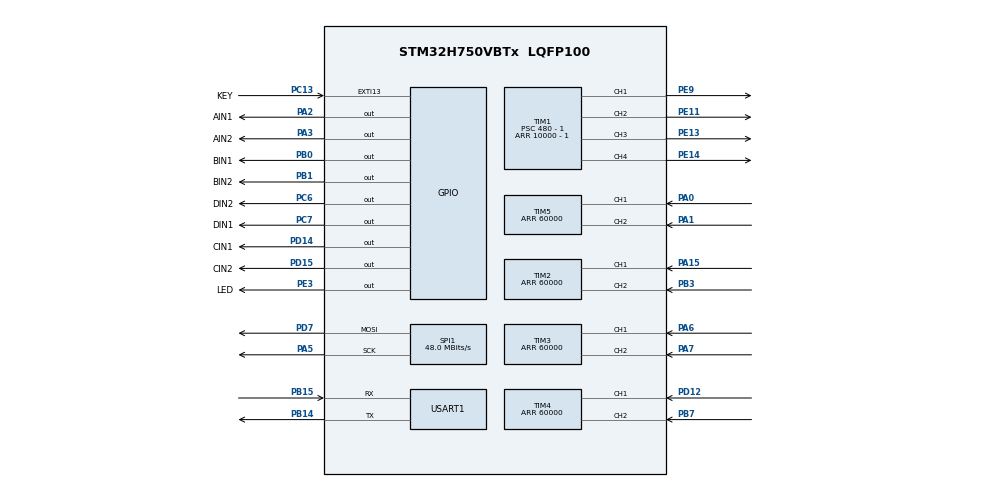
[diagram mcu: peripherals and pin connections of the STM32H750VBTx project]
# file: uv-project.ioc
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Dma.Request0=TIM2_UP
Dma.TIM2_UP.0.Direction=DMA_PERIPH_TO_MEMORY
Dma.TIM2_UP.0.EventEnable=DISABLE
Dma.TIM2_UP.0.FIFOMode=DMA_FIFOMODE_DISABLE
Dma.TIM2_UP.0.Instance=DMA1_Stream2
Dma.TIM2_UP.0.MemDataAlignment=DMA_MDATAALIGN_WORD
Dma.TIM2_UP.0.MemInc=DMA_MINC_ENABLE
Dma.TIM2_UP.0.Mode=DMA_NORMAL
Dma.TIM2_UP.0.PeriphDataAlignment=DMA_PDATAALIGN_WORD
Dma.TIM2_UP.0.PeriphInc=DMA_PINC_DISABLE
Dma.TIM2_UP.0.Polarity=HAL_DMAMUX_REQ_GEN_RISING
Dma.TIM2_UP.0.Priority=DMA_PRIORITY_LOW
Dma.TIM2_UP.0.RequestNumber=1
Dma.TIM2_UP.0.SignalID=NONE
Dma.TIM2_UP.0.SyncEnable=DISABLE
Dma.TIM2_UP.0.SyncPolarity=HAL_DMAMUX_SYNC_NO_EVENT
Dma.TIM2_UP.0.SyncRequestNumber=1
Dma.TIM2_UP.0.SyncSignalID=NONE
Mcu.Family=STM32H7
Mcu.Name=STM32H750VBTx
Mcu.Package=LQFP100
NVIC.DMA1_Stream2_IRQn=true\:0\:0\:false\:false\:true\:false\:true\:true
NVIC.EXTI15_10_IRQn=true\:0\:0\:false\:false\:true\:true\:true\:true
NVIC.PriorityGroup=NVIC_PRIORITYGROUP_4
NVIC.TIM16_IRQn=true\:0\:0\:false\:false\:true\:true\:true\:true
NVIC.TIM17_IRQn=true\:0\:0\:false\:false\:true\:true\:true\:true
NVIC.TIM2_IRQn=true\:0\:0\:false\:false\:true\:true\:true\:true
NVIC.USART1_IRQn=true\:0\:0\:false\:false\:true\:true\:true\:true
PA0.Signal=S_TIM5_CH1
PA1.Signal=S_TIM5_CH2
PA13\ (JTMS/SWDIO).Mode=Serial_Wire
PA13\ (JTMS/SWDIO).Signal=DEBUG_JTMS-SWDIO
PA14\ (JTCK/SWCLK).Mode=Serial_Wire
PA14\ (JTCK/SWCLK).Signal=DEBUG_JTCK-SWCLK
PA15\ (JTDI).GPIO_Speed=GPIO_SPEED_FREQ_HIGH
PA15\ (JTDI).Signal=S_TIM2_CH1_ETR
PA2.GPIO_Label=AIN1
PA2.Signal=GPIO_Output
PA3.GPIO_Label=AIN2
PA3.Signal=GPIO_Output
PA5.Mode=TX_Only_Simplex_Unidirect_Master
PA5.Signal=SPI1_SCK
PA6.Signal=S_TIM3_CH1
PA7.Signal=S_TIM3_CH2
PB0.GPIO_Label=BIN1
PB0.Signal=GPIO_Output
PB1.GPIO_Label=BIN2
PB1.Signal=GPIO_Output
PB14.Mode=Asynchronous
PB14.Signal=USART1_TX
PB15.Mode=Asynchronous
PB15.Signal=USART1_RX
PB3\ (JTDO/TRACESWO).GPIO_Speed=GPIO_SPEED_FREQ_HIGH
PB3\ (JTDO/TRACESWO).Signal=S_TIM2_CH2
PB7.Signal=S_TIM4_CH2
PC13.GPIO_Label=KEY
PC13.GPIO_ModeDefaultEXTI=GPIO_MODE_IT_RISING
PC13.GPIO_PuPd=GPIO_PULLDOWN
PC13.Signal=GPXTI13
PC6.GPIO_Label=DIN2
PC6.Signal=GPIO_Output
PC7.GPIO_Label=DIN1
PC7.Signal=GPIO_Output
PD12.Signal=S_TIM4_CH1
PD14.GPIO_Label=CIN1
PD14.Signal=GPIO_Output
PD15.GPIO_Label=CIN2
PD15.Signal=GPIO_Output
PD7.Mode=TX_Only_Simplex_Unidirect_Master
PD7.Signal=SPI1_MOSI
PE11.Signal=S_TIM1_CH2
PE13.Signal=S_TIM1_CH3
PE14.Signal=S_TIM1_CH4
PE3.GPIO_Label=LED
PE3.Signal=GPIO_Output
PE9.Signal=S_TIM1_CH1
PH0-OSC_IN\ (PH0).Mode=HSE-External-Oscillator
PH0-OSC_IN\ (PH0).Signal=RCC_OSC_IN
PH1-OSC_OUT\ (PH1).Mode=HSE-External-Oscillator
PH1-OSC_OUT\ (PH1).Signal=RCC_OSC_OUT
ProjectManager.HeapSize=0x200
ProjectManager.StackSize=0x400
ProjectManager.TargetToolchain=CMake
RCC.ADCFreq_Value=129000000
RCC.APB1Freq_Value=120000000
RCC.APB2Freq_Value=120000000
RCC.APB3Freq_Value=120000000
RCC.APB4Freq_Value=120000000
RCC.CortexFreq_Value=480000000
RCC.D1PPRE=RCC_APB3_DIV2
RCC.D2PPRE1=RCC_APB1_DIV2
RCC.D2PPRE2=RCC_APB2_DIV2
RCC.D3PPRE=RCC_APB4_DIV2
RCC.DIVM1=4
RCC.DIVN1=60
RCC.DIVQ1=5
RCC.HCLKFreq_Value=240000000
RCC.HPRE=RCC_HCLK_DIV2
RCC.PLL2FRACN=0
RCC.PLL3FRACN=0
RCC.PLLFRACN=0
RCC.SYSCLKFreq_VALUE=480000000
RCC.SYSCLKSource=RCC_SYSCLKSOURCE_PLLCLK
RCC.USBFreq_Value=192000000
SH.S_TIM1_CH1.0=TIM1_CH1,PWM Generation1 CH1
SH.S_TIM1_CH2.0=TIM1_CH2,PWM Generation2 CH2
SH.S_TIM1_CH3.0=TIM1_CH3,PWM Generation3 CH3
SH.S_TIM1_CH4.0=TIM1_CH4,PWM Generation4 CH4
SH.S_TIM2_CH1_ETR.0=TIM2_CH1,Encoder_Interface
SH.S_TIM2_CH2.0=TIM2_CH2,Encoder_Interface
SH.S_TIM3_CH1.0=TIM3_CH1,Encoder_Interface
SH.S_TIM3_CH2.0=TIM3_CH2,Encoder_Interface
SH.S_TIM4_CH1.0=TIM4_CH1,Encoder_Interface
SH.S_TIM4_CH2.0=TIM4_CH2,Encoder_Interface
SH.S_TIM5_CH1.0=TIM5_CH1,Encoder_Interface
SH.S_TIM5_CH2.0=TIM5_CH2,Encoder_Interface
SPI1.BaudRatePrescaler=SPI_BAUDRATEPRESCALER_4
SPI1.CalculateBaudRate=48.0 MBits/s
SPI1.Direction=SPI_DIRECTION_2LINES_TXONLY
SPI1.Mode=SPI_MODE_MASTER
SPI1.VirtualType=VM_MASTER
TIM1.Channel-PWM\ Generation1\ CH1=TIM_CHANNEL_1
TIM1.Channel-PWM\ Generation2\ CH2=TIM_CHANNEL_2
TIM1.Channel-PWM\ Generation3\ CH3=TIM_CHANNEL_3
TIM1.Channel-PWM\ Generation4\ CH4=TIM_CHANNEL_4
TIM1.OCIdleState_1=TIM_OCIDLESTATE_RESET
TIM1.OCPolarity_1=TIM_OCPOLARITY_HIGH
TIM1.OCPolarity_2=TIM_OCPOLARITY_HIGH
TIM1.OCPolarity_3=TIM_OCPOLARITY_HIGH
TIM1.OCPolarity_4=TIM_OCPOLARITY_HIGH
TIM1.Period=10000 - 1
TIM1.Prescaler=480 - 1
TIM16.Period=1000-1
TIM16.Prescaler=240-1
TIM17.Period=1000-1
TIM17.Prescaler=240-1
TIM2.AutoReloadPreload=TIM_AUTORELOAD_PRELOAD_ENABLE
TIM2.EncoderMode=TIM_ENCODERMODE_TI12
TIM2.IC1Filter=6
TIM2.IC2Filter=6
TIM2.Period=60000
TIM3.AutoReloadPreload=TIM_AUTORELOAD_PRELOAD_ENABLE
TIM3.EncoderMode=TIM_ENCODERMODE_TI12
TIM3.IC1Filter=6
TIM3.IC2Filter=6
TIM3.Period=60000
TIM4.AutoReloadPreload=TIM_AUTORELOAD_PRELOAD_ENABLE
TIM4.EncoderMode=TIM_ENCODERMODE_TI12
TIM4.IC1Filter=6
TIM4.IC2Filter=6
TIM4.Period=60000
TIM5.AutoReloadPreload=TIM_AUTORELOAD_PRELOAD_ENABLE
TIM5.EncoderMode=TIM_ENCODERMODE_TI12
TIM5.IC1Filter=6
TIM5.IC2Filter=6
TIM5.Period=60000
USART1.VirtualMode-Asynchronous=VM_ASYNC
VP_MEMORYMAP_VS_MEMORYMAP.Mode=CurAppReg
VP_TIM16_VS_ClockSourceINT.Mode=Enable_Timer
VP_TIM17_VS_ClockSourceINT.Mode=Enable_Timer
VP_TIM1_VS_ClockSourceINT.Mode=Internal
board=custom

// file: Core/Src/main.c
/* USER CODE BEGIN Header */
/**
 ******************************************************************************
 * @file           : main.c
 * @brief          : Main program body
 ******************************************************************************
 * @attention
 *
 * Copyright (c) 2024 STMicroelectronics.
 * All rights reserved.
 *
 * This software is licensed under terms that can be found in the LICENSE file
 * in the root directory of this software component.
 * If no LICENSE file comes with this software, it is provided AS-IS.
 *
 ******************************************************************************
 */
/* USER CODE END Header */
#include "main.h"
#include "dma.h"
#include "memorymap.h"
#include "spi.h"
#include "tim.h"
#include "usart.h"
#include "gpio.h"

/* USER CODE BEGIN Includes */

#include "entrypoint.hh"

/* USER CODE END Includes */

void SystemClock_Config(void);

int main(void)
{

  /* MCU Configuration--------------------------------------------------------*/

  /* Reset of all peripherals, Initializes the Flash interface and the Systick. */
  HAL_Init();

  /* Configure the system clock */
  SystemClock_Config();

  /* Initialize all configured peripherals */
  MX_GPIO_Init();
  MX_DMA_Init();
  MX_TIM1_Init();
  MX_TIM2_Init();
  MX_TIM3_Init();
  MX_TIM4_Init();
  MX_TIM5_Init();
  MX_SPI1_Init();
  MX_TIM17_Init();
  MX_USART1_UART_Init();
  MX_TIM16_Init();
  /* USER CODE BEGIN 2 */

    entrypoint();

  /* USER CODE END 2 */

  /* Infinite loop */
    while (1) {

    }
}

void SystemClock_Config(void)
{
  RCC_OscInitTypeDef RCC_OscInitStruct = {0};
  RCC_ClkInitTypeDef RCC_ClkInitStruct = {0};

  /** Supply configuration update enable
  */
  HAL_PWREx_ConfigSupply(PWR_LDO_SUPPLY);

  /** Configure the main internal regulator output voltage
  */
  __HAL_PWR_VOLTAGESCALING_CONFIG(PWR_REGULATOR_VOLTAGE_SCALE1);

  while(!__HAL_PWR_GET_FLAG(PWR_FLAG_VOSRDY)) {}

  __HAL_RCC_SYSCFG_CLK_ENABLE();
  __HAL_PWR_VOLTAGESCALING_CONFIG(PWR_REGULATOR_VOLTAGE_SCALE0);

  while(!__HAL_PWR_GET_FLAG(PWR_FLAG_VOSRDY)) {}

  /** Initializes the RCC Oscillators according to the specified parameters
  * in the RCC_OscInitTypeDef structure.
  */
  RCC_OscInitStruct.OscillatorType = RCC_OSCILLATORTYPE_HSI;
  RCC_OscInitStruct.HSIState = RCC_HSI_DIV1;
  RCC_OscInitStruct.HSICalibrationValue = RCC_HSICALIBRATION_DEFAULT;
  RCC_OscInitStruct.PLL.PLLState = RCC_PLL_ON;
  RCC_OscInitStruct.PLL.PLLSource = RCC_PLLSOURCE_HSI;
  RCC_OscInitStruct.PLL.PLLM = 4;
  RCC_OscInitStruct.PLL.PLLN = 60;
  RCC_OscInitStruct.PLL.PLLP = 2;
  RCC_OscInitStruct.PLL.PLLQ = 5;
  RCC_OscInitStruct.PLL.PLLR = 2;
  RCC_OscInitStruct.PLL.PLLRGE = RCC_PLL1VCIRANGE_3;
  RCC_OscInitStruct.PLL.PLLVCOSEL = RCC_PLL1VCOWIDE;
  RCC_OscInitStruct.PLL.PLLFRACN = 0;
  if (HAL_RCC_OscConfig(&RCC_OscInitStruct) != HAL_OK)
  {
    Error_Handler();
  }

  /** Initializes the CPU, AHB and APB buses clocks
  */
  RCC_ClkInitStruct.ClockType = RCC_CLOCKTYPE_HCLK|RCC_CLOCKTYPE_SYSCLK
                              |RCC_CLOCKTYPE_PCLK1|RCC_CLOCKTYPE_PCLK2
                              |RCC_CLOCKTYPE_D3PCLK1|RCC_CLOCKTYPE_D1PCLK1;
  RCC_ClkInitStruct.SYSCLKSource = RCC_SYSCLKSOURCE_PLLCLK;
  RCC_ClkInitStruct.SYSCLKDivider = RCC_SYSCLK_DIV1;
  RCC_ClkInitStruct.AHBCLKDivider = RCC_HCLK_DIV2;
  RCC_ClkInitStruct.APB3CLKDivider = RCC_APB3_DIV2;
  RCC_ClkInitStruct.APB1CLKDivider = RCC_APB1_DIV2;
  RCC_ClkInitStruct.APB2CLKDivider = RCC_APB2_DIV2;
  RCC_ClkInitStruct.APB4CLKDivider = RCC_APB4_DIV2;

  if (HAL_RCC_ClockConfig(&RCC_ClkInitStruct, FLASH_LATENCY_4) != HAL_OK)
  {
    Error_Handler();
  }
}

void Error_Handler(void)
{
    __disable_irq();
    while (1) {
    }
}
